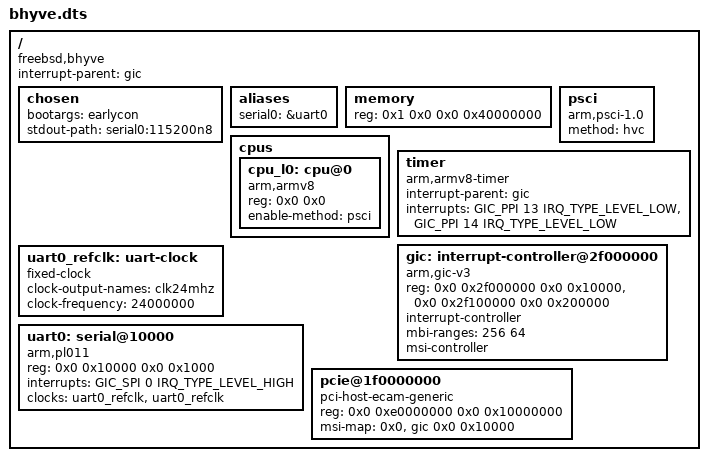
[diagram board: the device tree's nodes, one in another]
/dts-v1/;

#include <dt-bindings/interrupt-controller/arm-gic.h>
#include <dt-bindings/interrupt-controller/irq.h>

/ {
	compatible = "freebsd,bhyve";

	interrupt-parent = <&gic>;
	#address-cells = <2>;
	#size-cells = <2>;

	chosen {
		bootargs = "earlycon";
		stdout-path = "serial0:115200n8";
	};

	aliases {
		serial0 = &uart0;
	};

	memory {
		reg = <0x1 0x0 0x0 0x40000000>;
	};

	cpus {
		#address-cells = <2>;
		#size-cells = <0>;

		cpu_l0: cpu@0 {
			device_type = "cpu";
			compatible = "arm,armv8";
			reg = <0x0 0x0>;
			enable-method = "psci";
		};
	};

	psci {
		compatible = "arm,psci-1.0";
		method = "hvc";
	};

	timer {
		compatible = "arm,armv8-timer";
		interrupt-parent = <&gic>;
		interrupts = <GIC_PPI 13 IRQ_TYPE_LEVEL_LOW>,
			     <GIC_PPI 14 IRQ_TYPE_LEVEL_LOW>;
	};

	gic: interrupt-controller@2f000000 {
		compatible = "arm,gic-v3";
		reg = <0x0 0x2f000000 0x0 0x10000>,	/* GICD */
		      <0x0 0x2f100000 0x0 0x200000>;	/* GICR */
		#interrupt-cells = <3>;
		interrupt-controller;
		mbi-ranges = <256 64>;
		msi-controller;
	};

	uart0_refclk: uart-clock {
		compatible = "fixed-clock";
		clock-output-names = "clk24mhz";
		#clock-cells = <0>;
		clock-frequency = <24000000>;
	};

	uart0: serial@10000 {
		compatible = "arm,pl011", "arm,primecell";
		reg = <0x0 0x10000 0x0 0x1000>;
		interrupts = <GIC_SPI 0 IRQ_TYPE_LEVEL_HIGH>;
		clocks = <&uart0_refclk>, <&uart0_refclk>;
		clock-names = "uartclk", "apb_pclk";
	};

	pcie@1f0000000 {
		compatible = "pci-host-ecam-generic";
		#address-cells = <3>;
		#size-cells = <2>;
		device_type = "pci";
		reg = <0x0 0xe0000000 0x0 0x10000000>;
		ranges = <0x01000000 0x0 0xdf000000 0x0 0xdf000000 0x0 0x01000000>,
		         <0x02000000 0x0 0xa0000000 0x0 0xa0000000 0x0 0x3f000000>;
		msi-map = <0x0 &gic 0x0 0x10000>;
	};
};
